# STM32WL5X_CM0P register map
File version: 2.1
CPU: CM0 r0p1, little endian, MPU, no FPU, 4 interrupt priority bits
Registers are 32-bit, read-write, reset 0x0 unless marked. A register's access mark holds for its fields unless they carry their own. Offsets are from the block's base; [hi:lo] are bit positions; {n}, {i} and the like mark numbered series.

## DAC — Digital-to-analog converter
Base 0x40007400
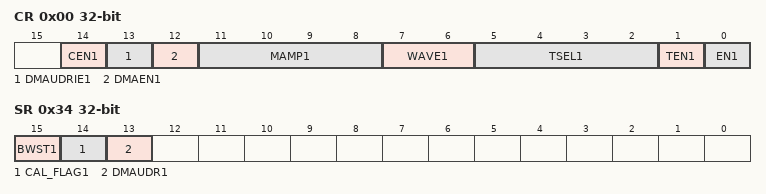
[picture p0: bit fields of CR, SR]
0x00 CR — control register
  [n+13] CEN{n} (n=1..1) — DAC channel{n} calibration enable
    0=Normal (DAC Channel X Normal operating mode); 1=Calibration (DAC Channel X calibration mode)
  [n+12] DMAUDRIE{n} (n=1..1) — DAC channel{n} DMA Underrun Interrupt enable
    0=Disabled (DAC channel X DMA Underrun Interrupt disabled); 1=Enabled (DAC channel X DMA Underrun Interrupt enabled)
  [n+11] DMAEN{n} (n=1..1) — DAC channel{n} DMA enable
    0=Disabled (DAC Channel X DMA mode disabled); 1=Enabled (DAC Channel X DMA mode enabled)
  [n+10:n+7] MAMP{n} (n=1..1) — DAC channel{n} mask/amplitude selector
    0=Amp1 (Unmask bit0 of LFSR/ triangle amplitude equal to 1); 1=Amp3 (Unmask bits[1:0] of LFSR/ triangle amplitude equal to 3); 2=Amp7 (Unmask bits[2:0] of LFSR/ triangle amplitude equal to 7); 3=Amp15 (Unmask bits[3:0] of LFSR/ triangle amplitude equal to 15); 4=Amp31 (Unmask bits[4:0] of LFSR/ triangle amplitude equal to 31); 5=Amp63 (Unmask bits[5:0] of LFSR/ triangle amplitude equal 63); 6=Amp127 (Unmask bits[6:0] of LFSR/ triangle amplitude equal to 127); 7=Amp255 (Unmask bits[7:0] of LFSR/ triangle amplitude equal to 255); 8=Amp511 (Unmask bits[8:0] of LFSR/ triangle amplitude equal to 511); 9=Amp1023 (Unmask bits[9:0] of LFSR/ triangle amplitude equal to 1023); 10=Amp2047 (Unmask bits[10:0] of LFSR/ triangle amplitude equal to 2047); other=Amp4095 (Unmask bits[11:0] of LFSR/ triangle amplitude equal to 4095)
  [n+6:n+5] WAVE{n} (n=1..1) — DAC channel{n} noise/triangle wave generation enable
    0=Disabled (Wave generation disabled); 1=Noise wave generation enabled; other=Triangle wave generation enabled
  [5:2] TSEL1 — DAC channel1 trigger selection
    0=Swtrig (Software trigger); 1=Tim1Trgo (Timer 1 TRGO event); 2=Tim2Trgo (Timer 2 TRGO event); 11=LPTIM1 OUT event; 12=LPTIM2 OUT event; 13=LPTIM3 OUT event; 14=EXTI9 (dac_chx_trg14)
  [n] TEN{n} (n=1..1) — DAC channel{n} trigger enable
    0=Disabled (DAC Channel X trigger disabled); 1=Enabled (DAC Channel X trigger enabled)
  [n-1] EN{n} (n=1..1) — DAC channel{n} enable
    0=Disabled (DAC Channel X disabled); 1=Enabled (DAC Channel X enabled)
0x04 SWTRGR wo — software trigger register
  [n-1] SWTRIG{n} (n=1..1) — DAC channel{n} software trigger
    0=NoTrigger; 1=Trigger
{0x4+4i} DHR12R{i} (i=1..1) — channel{i} 12-bit right-aligned data holding register
  [11:0] DACCDHR — DAC channel1 12-bit right-aligned data
{0x8+4i} DHR12L{i} (i=1..1) — channel{i} 12-bit left aligned data holding register
  [15:4] DACCDHR — DAC channel1 12-bit left-aligned data
{0xC+4i} DHR8R{i} (i=1..1) — channel{i} 8-bit right aligned data holding register
  [7:0] DACCDHR — DAC channel1 8-bit right-aligned data
0x20 DHR12RD — Dual DAC 12-bit right-aligned data holding register
  [n+10:n-1] DACC{n}DHR (n=1..1) — DAC channel{n} 12-bit right-aligned data
0x24 DHR12LD — Dual DAC 12-bit left aligned data holding register
  [n+14:n+3] DACC{n}DHR (n=1..1) — DAC channel{n} 12-bit left-aligned data
0x28 DHR8RD — Dual DAC 8-bit right aligned data holding register
  [n+6:n-1] DACC{n}DHR (n=1..1) — DAC channel{n} 8-bit right-aligned data
{0x28+4i} DOR{i} (i=1..1) ro — channel{i} data output register
  [11:0] DACCDOR — DACC1DOR
0x34 SR access per field — status register
  [n+14] BWST{n} (n=1..1) ro — DAC channel{n} busy writing sample time flag
    0=Idle (There is no write operation of DAC_SHSR1 ongoing: DAC_SHSR1 can be written); 1=Busy (There is a write operation of DAC_SHSR1 ongoing: DAC_SHSR1 cannot be written)
  [n+13] CAL_FLAG{n} (n=1..1) ro — DAC channel{n} calibration offset status
    0=Lower (Calibration trimming value is lower than the offset correction value); 1=Equal_Higher (Calibration trimming value is equal or greater than the offset correction value)
  [n+12] DMAUDR{n} (n=1..1) rw — DAC channel{n} DMA underrun flag
    0=NoUnderrun (No DMA underrun error condition occurred for DAC channel x); 1=Underrun (DMA underrun error condition occurred for DAC channel x (the currently selected trigger is driving DAC channel1 conversion at a frequency higher than the DMA service capability rate))
0x38 CCR — calibration control register
  [n+3:n-1] OTRIM{n} (n=1..1) — DAC channel{n} offset trimming value
0x3C MCR — mode control register
  [n+1:n-1] MODE{n} (n=1..1) — DAC channel{n} mode
    0=NormalPinBuffer (Normal mode - DAC channelx is connected to external pin with Buffer enabled); 1=NormalPinChipBuffer (Normal mode - DAC channelx is connected to external pin and to on chip peripherals with Buffer enabled); 2=NormalPinNoBuffer (Normal mode - DAC channelx is connected to external pin with Buffer disabled); 3=NormalChipNoBuffer (Normal mode - DAC channelx is connected to on chip peripherals with Buffer disabled); 4=SHPinBuffer (S&H mode - DAC channelx is connected to external pin with Buffer enabled); 5=SHPinChipBuffer (S&H mode - DAC channelx is connected to external pin and to on chip peripherals with Buffer enabled); 6=SHPinNoBuffer (S&H mode - DAC channelx is connected to external pin and to on chip peripherals with Buffer disabled); 7=SHChipNoBuffer (S&H mode - DAC channelx is connected to on chip peripherals with Buffer disabled)
{0x3C+4i} SHSR{i} (i=1..1) — DAC channel{i} sample and hold sample time register
  [9:0] TSAMPLE — DAC Channel 1 sample Time (only valid in Sample and Hold mode)
0x48 SHHR reset 0x10001 — Sample and Hold hold time register
  [n+8:n-1] THOLD{n} (n=1..1) — DAC channel{n} hold time (only valid in Sample and hold mode)
0x4C SHRR reset 0x10001 — Sample and Hold refresh time register
  [n+6:n-1] TREFRESH{n} (n=1..1) — DAC channel{n} refresh time (only valid in Sample and hold mode)
